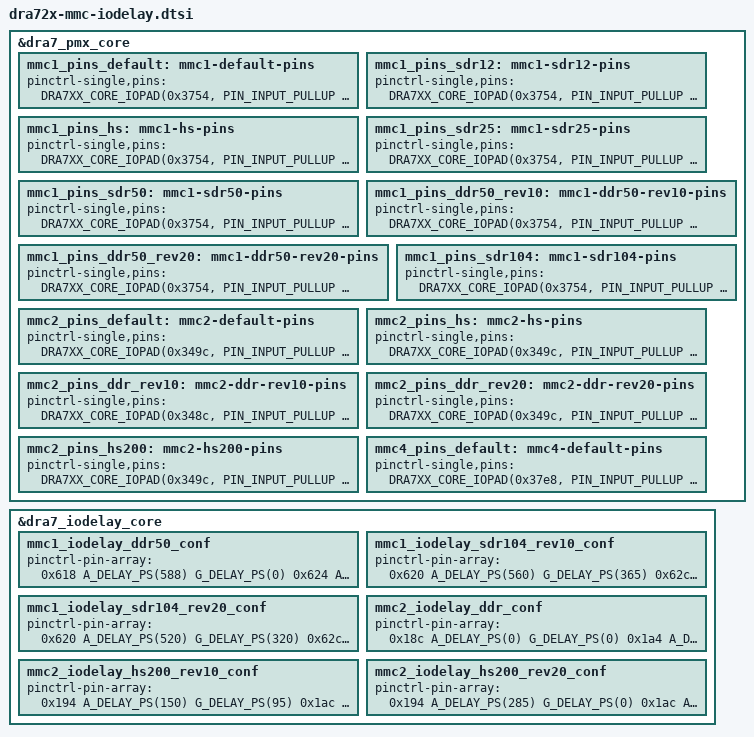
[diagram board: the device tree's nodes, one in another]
&dra7_pmx_core {
	mmc1_pins_default: mmc1-default-pins {
		pinctrl-single,pins = <
			DRA7XX_CORE_IOPAD(0x3754, PIN_INPUT_PULLUP | MUX_MODE0)  
			DRA7XX_CORE_IOPAD(0x3758, PIN_INPUT_PULLUP | MUX_MODE0)  
			DRA7XX_CORE_IOPAD(0x375c, PIN_INPUT_PULLUP | MUX_MODE0)  
			DRA7XX_CORE_IOPAD(0x3760, PIN_INPUT_PULLUP | MUX_MODE0)  
			DRA7XX_CORE_IOPAD(0x3764, PIN_INPUT_PULLUP | MUX_MODE0)  
			DRA7XX_CORE_IOPAD(0x3768, PIN_INPUT_PULLUP | MUX_MODE0)  
		>;
	};
	mmc1_pins_sdr12: mmc1-sdr12-pins {
		pinctrl-single,pins = <
			DRA7XX_CORE_IOPAD(0x3754, PIN_INPUT_PULLUP | MUX_MODE0)	 
			DRA7XX_CORE_IOPAD(0x3758, PIN_INPUT_PULLUP | MUX_MODE0)	 
			DRA7XX_CORE_IOPAD(0x375c, PIN_INPUT_PULLUP | MUX_MODE0)	 
			DRA7XX_CORE_IOPAD(0x3760, PIN_INPUT_PULLUP | MUX_MODE0)	 
			DRA7XX_CORE_IOPAD(0x3764, PIN_INPUT_PULLUP | MUX_MODE0)	 
			DRA7XX_CORE_IOPAD(0x3768, PIN_INPUT_PULLUP | MUX_MODE0)	 
		>;
	};
	mmc1_pins_hs: mmc1-hs-pins {
		pinctrl-single,pins = <
			DRA7XX_CORE_IOPAD(0x3754, PIN_INPUT_PULLUP | MUX_MODE0)  
			DRA7XX_CORE_IOPAD(0x3758, PIN_INPUT_PULLUP | MUX_MODE0)  
			DRA7XX_CORE_IOPAD(0x375c, PIN_INPUT_PULLUP | MUX_MODE0)  
			DRA7XX_CORE_IOPAD(0x3760, PIN_INPUT_PULLUP | MUX_MODE0)  
			DRA7XX_CORE_IOPAD(0x3764, PIN_INPUT_PULLUP | MUX_MODE0)  
			DRA7XX_CORE_IOPAD(0x3768, PIN_INPUT_PULLUP | MUX_MODE0)  
		>;
	};
	mmc1_pins_sdr25: mmc1-sdr25-pins {
		pinctrl-single,pins = <
			DRA7XX_CORE_IOPAD(0x3754, PIN_INPUT_PULLUP | MUX_MODE0)	 
			DRA7XX_CORE_IOPAD(0x3758, PIN_INPUT_PULLUP | MUX_MODE0)	 
			DRA7XX_CORE_IOPAD(0x375c, PIN_INPUT_PULLUP | MUX_MODE0)	 
			DRA7XX_CORE_IOPAD(0x3760, PIN_INPUT_PULLUP | MUX_MODE0)	 
			DRA7XX_CORE_IOPAD(0x3764, PIN_INPUT_PULLUP | MUX_MODE0)	 
			DRA7XX_CORE_IOPAD(0x3768, PIN_INPUT_PULLUP | MUX_MODE0)	 
		>;
	};
	mmc1_pins_sdr50: mmc1-sdr50-pins {
		pinctrl-single,pins = <
			DRA7XX_CORE_IOPAD(0x3754, PIN_INPUT_PULLUP | MUX_VIRTUAL_MODE15 | MUX_MODE0)	 
			DRA7XX_CORE_IOPAD(0x3758, PIN_INPUT_PULLUP | MUX_VIRTUAL_MODE15 | MUX_MODE0)	 
			DRA7XX_CORE_IOPAD(0x375c, PIN_INPUT_PULLUP | MUX_VIRTUAL_MODE15 | MUX_MODE0)	 
			DRA7XX_CORE_IOPAD(0x3760, PIN_INPUT_PULLUP | MUX_VIRTUAL_MODE15 | MUX_MODE0)	 
			DRA7XX_CORE_IOPAD(0x3764, PIN_INPUT_PULLUP | MUX_VIRTUAL_MODE15 | MUX_MODE0)	 
			DRA7XX_CORE_IOPAD(0x3768, PIN_INPUT_PULLUP | MUX_VIRTUAL_MODE15 | MUX_MODE0)	 
		>;
	};
	mmc1_pins_ddr50_rev10: mmc1-ddr50-rev10-pins {
		pinctrl-single,pins = <
			DRA7XX_CORE_IOPAD(0x3754, PIN_INPUT_PULLUP | MUX_VIRTUAL_MODE14 | MUX_MODE0)	 
			DRA7XX_CORE_IOPAD(0x3758, PIN_INPUT_PULLUP | MUX_VIRTUAL_MODE14 | MUX_MODE0)	 
			DRA7XX_CORE_IOPAD(0x375C, PIN_INPUT_PULLUP | MUX_VIRTUAL_MODE14 | MUX_MODE0)	 
			DRA7XX_CORE_IOPAD(0x3760, PIN_INPUT_PULLUP | MUX_VIRTUAL_MODE14 | MUX_MODE0)	 
			DRA7XX_CORE_IOPAD(0x3764, PIN_INPUT_PULLUP | MUX_VIRTUAL_MODE14 | MUX_MODE0)	 
			DRA7XX_CORE_IOPAD(0x3768, PIN_INPUT_PULLUP | MUX_VIRTUAL_MODE14 | MUX_MODE0)	 
		>;
	};
	mmc1_pins_ddr50_rev20: mmc1-ddr50-rev20-pins {
		pinctrl-single,pins = <
			DRA7XX_CORE_IOPAD(0x3754, PIN_INPUT_PULLUP | MODE_SELECT | MUX_MODE0)	 
			DRA7XX_CORE_IOPAD(0x3758, PIN_INPUT_PULLUP | MODE_SELECT | MUX_MODE0)	 
			DRA7XX_CORE_IOPAD(0x375c, PIN_INPUT_PULLUP | MODE_SELECT | MUX_MODE0)	 
			DRA7XX_CORE_IOPAD(0x3760, PIN_INPUT_PULLUP | MODE_SELECT | MUX_MODE0)	 
			DRA7XX_CORE_IOPAD(0x3764, PIN_INPUT_PULLUP | MODE_SELECT | MUX_MODE0)	 
			DRA7XX_CORE_IOPAD(0x3768, PIN_INPUT_PULLUP | MODE_SELECT | MUX_MODE0)	 
		>;
	};
	mmc1_pins_sdr104: mmc1-sdr104-pins {
		pinctrl-single,pins = <
			DRA7XX_CORE_IOPAD(0x3754, PIN_INPUT_PULLUP | MODE_SELECT | MUX_MODE0)	 
			DRA7XX_CORE_IOPAD(0x3758, PIN_INPUT_PULLUP | MODE_SELECT | MUX_MODE0)	 
			DRA7XX_CORE_IOPAD(0x375c, PIN_INPUT_PULLUP | MODE_SELECT | MUX_MODE0)	 
			DRA7XX_CORE_IOPAD(0x3760, PIN_INPUT_PULLUP | MODE_SELECT | MUX_MODE0)	 
			DRA7XX_CORE_IOPAD(0x3764, PIN_INPUT_PULLUP | MODE_SELECT | MUX_MODE0)	 
			DRA7XX_CORE_IOPAD(0x3768, PIN_INPUT_PULLUP | MODE_SELECT | MUX_MODE0)	 
		>;
	};
	mmc2_pins_default: mmc2-default-pins {
		pinctrl-single,pins = <
			DRA7XX_CORE_IOPAD(0x349c, PIN_INPUT_PULLUP | MUX_MODE1)  
			DRA7XX_CORE_IOPAD(0x34b0, PIN_INPUT_PULLUP | MUX_MODE1)  
			DRA7XX_CORE_IOPAD(0x34a0, PIN_INPUT_PULLUP | MUX_MODE1)  
			DRA7XX_CORE_IOPAD(0x34a4, PIN_INPUT_PULLUP | MUX_MODE1)  
			DRA7XX_CORE_IOPAD(0x34a8, PIN_INPUT_PULLUP | MUX_MODE1)  
			DRA7XX_CORE_IOPAD(0x34ac, PIN_INPUT_PULLUP | MUX_MODE1)  
			DRA7XX_CORE_IOPAD(0x348c, PIN_INPUT_PULLUP | MUX_MODE1)  
			DRA7XX_CORE_IOPAD(0x3490, PIN_INPUT_PULLUP | MUX_MODE1)  
			DRA7XX_CORE_IOPAD(0x3494, PIN_INPUT_PULLUP | MUX_MODE1)  
			DRA7XX_CORE_IOPAD(0x3498, PIN_INPUT_PULLUP | MUX_MODE1)  
		>;
	};
	mmc2_pins_hs: mmc2-hs-pins {
		pinctrl-single,pins = <
			DRA7XX_CORE_IOPAD(0x349c, PIN_INPUT_PULLUP | MUX_MODE1)  
			DRA7XX_CORE_IOPAD(0x34b0, PIN_INPUT_PULLUP | MUX_MODE1)  
			DRA7XX_CORE_IOPAD(0x34a0, PIN_INPUT_PULLUP | MUX_MODE1)  
			DRA7XX_CORE_IOPAD(0x34a4, PIN_INPUT_PULLUP | MUX_MODE1)  
			DRA7XX_CORE_IOPAD(0x34a8, PIN_INPUT_PULLUP | MUX_MODE1)  
			DRA7XX_CORE_IOPAD(0x34ac, PIN_INPUT_PULLUP | MUX_MODE1)  
			DRA7XX_CORE_IOPAD(0x348c, PIN_INPUT_PULLUP | MUX_MODE1)  
			DRA7XX_CORE_IOPAD(0x3490, PIN_INPUT_PULLUP | MUX_MODE1)  
			DRA7XX_CORE_IOPAD(0x3494, PIN_INPUT_PULLUP | MUX_MODE1)  
			DRA7XX_CORE_IOPAD(0x3498, PIN_INPUT_PULLUP | MUX_MODE1)  
		>;
	};
	mmc2_pins_ddr_rev10: mmc2-ddr-rev10-pins {
		pinctrl-single,pins = <
			DRA7XX_CORE_IOPAD(0x348c, PIN_INPUT_PULLUP | MUX_MODE1)	 
			DRA7XX_CORE_IOPAD(0x3490, PIN_INPUT_PULLUP | MUX_MODE1)	 
			DRA7XX_CORE_IOPAD(0x3494, PIN_INPUT_PULLUP | MUX_MODE1)	 
			DRA7XX_CORE_IOPAD(0x3498, PIN_INPUT_PULLUP | MUX_MODE1)	 
			DRA7XX_CORE_IOPAD(0x349c, PIN_INPUT_PULLUP | MUX_MODE1)	 
			DRA7XX_CORE_IOPAD(0x34a0, PIN_INPUT_PULLUP | MUX_MODE1)	 
			DRA7XX_CORE_IOPAD(0x34a4, PIN_INPUT_PULLUP | MUX_MODE1)	 
			DRA7XX_CORE_IOPAD(0x34a8, PIN_INPUT_PULLUP | MUX_MODE1)	 
			DRA7XX_CORE_IOPAD(0x34ac, PIN_INPUT_PULLUP | MUX_MODE1)	 
			DRA7XX_CORE_IOPAD(0x34b0, PIN_INPUT_PULLUP | MUX_MODE1)	 
		>;
	};
	mmc2_pins_ddr_rev20: mmc2-ddr-rev20-pins {
		pinctrl-single,pins = <
			DRA7XX_CORE_IOPAD(0x349c, PIN_INPUT_PULLUP | MODE_SELECT | MUX_MODE1)  
			DRA7XX_CORE_IOPAD(0x34b0, PIN_INPUT_PULLUP | MODE_SELECT | MUX_MODE1)  
			DRA7XX_CORE_IOPAD(0x34a0, PIN_INPUT_PULLUP | MODE_SELECT | MUX_MODE1)  
			DRA7XX_CORE_IOPAD(0x34a4, PIN_INPUT_PULLUP | MODE_SELECT | MUX_MODE1)  
			DRA7XX_CORE_IOPAD(0x34a8, PIN_INPUT_PULLUP | MODE_SELECT | MUX_MODE1)  
			DRA7XX_CORE_IOPAD(0x34ac, PIN_INPUT_PULLUP | MODE_SELECT | MUX_MODE1)  
			DRA7XX_CORE_IOPAD(0x348c, PIN_INPUT_PULLUP | MODE_SELECT | MUX_MODE1)  
			DRA7XX_CORE_IOPAD(0x3490, PIN_INPUT_PULLUP | MODE_SELECT | MUX_MODE1)  
			DRA7XX_CORE_IOPAD(0x3494, PIN_INPUT_PULLUP | MODE_SELECT | MUX_MODE1)  
			DRA7XX_CORE_IOPAD(0x3498, PIN_INPUT_PULLUP | MODE_SELECT | MUX_MODE1)  
		>;
	};
	mmc2_pins_hs200: mmc2-hs200-pins {
		pinctrl-single,pins = <
			DRA7XX_CORE_IOPAD(0x349c, PIN_INPUT_PULLUP | MODE_SELECT | MUX_MODE1)  
			DRA7XX_CORE_IOPAD(0x34b0, PIN_INPUT_PULLUP | MODE_SELECT | MUX_MODE1)  
			DRA7XX_CORE_IOPAD(0x34a0, PIN_INPUT_PULLUP | MODE_SELECT | MUX_MODE1)  
			DRA7XX_CORE_IOPAD(0x34a4, PIN_INPUT_PULLUP | MODE_SELECT | MUX_MODE1)  
			DRA7XX_CORE_IOPAD(0x34a8, PIN_INPUT_PULLUP | MODE_SELECT | MUX_MODE1)  
			DRA7XX_CORE_IOPAD(0x34ac, PIN_INPUT_PULLUP | MODE_SELECT | MUX_MODE1)  
			DRA7XX_CORE_IOPAD(0x348c, PIN_INPUT_PULLUP | MODE_SELECT | MUX_MODE1)  
			DRA7XX_CORE_IOPAD(0x3490, PIN_INPUT_PULLUP | MODE_SELECT | MUX_MODE1)  
			DRA7XX_CORE_IOPAD(0x3494, PIN_INPUT_PULLUP | MODE_SELECT | MUX_MODE1)  
			DRA7XX_CORE_IOPAD(0x3498, PIN_INPUT_PULLUP | MODE_SELECT | MUX_MODE1)  
		>;
	};
	mmc4_pins_default: mmc4-default-pins {
		pinctrl-single,pins = <
			DRA7XX_CORE_IOPAD(0x37e8, PIN_INPUT_PULLUP | MUX_MODE3)  
			DRA7XX_CORE_IOPAD(0x37ec, PIN_INPUT_PULLUP | MUX_MODE3)  
			DRA7XX_CORE_IOPAD(0x37f0, PIN_INPUT_PULLUP | MUX_MODE3)  
			DRA7XX_CORE_IOPAD(0x37f4, PIN_INPUT_PULLUP | MUX_MODE3)  
			DRA7XX_CORE_IOPAD(0x37f8, PIN_INPUT_PULLUP | MUX_MODE3)  
			DRA7XX_CORE_IOPAD(0x37fc, PIN_INPUT_PULLUP | MUX_MODE3)  
		>;
	};
};
&dra7_iodelay_core {
	mmc1_iodelay_ddr50_conf: mmc1_iodelay_ddr50_conf {
		pinctrl-pin-array = <
			0x618 A_DELAY_PS(588) G_DELAY_PS(0)	 
			0x624 A_DELAY_PS(1000) G_DELAY_PS(0)	 
			0x630 A_DELAY_PS(1375) G_DELAY_PS(0)	 
			0x63C A_DELAY_PS(1000) G_DELAY_PS(0)	 
			0x648 A_DELAY_PS(1000) G_DELAY_PS(0)	 
			0x654 A_DELAY_PS(1000) G_DELAY_PS(0)	 
			0x620 A_DELAY_PS(1230) G_DELAY_PS(0)	 
			0x62C A_DELAY_PS(0) G_DELAY_PS(0)	 
			0x638 A_DELAY_PS(56) G_DELAY_PS(0)	 
			0x644 A_DELAY_PS(76) G_DELAY_PS(0)	 
			0x650 A_DELAY_PS(91) G_DELAY_PS(0)	 
			0x65C A_DELAY_PS(99) G_DELAY_PS(0)	 
			0x628 A_DELAY_PS(0) G_DELAY_PS(0)	 
			0x634 A_DELAY_PS(0) G_DELAY_PS(0)	 
			0x640 A_DELAY_PS(0) G_DELAY_PS(0)	 
			0x64C A_DELAY_PS(0) G_DELAY_PS(0)	 
			0x658 A_DELAY_PS(0) G_DELAY_PS(0)	 
		>;
	};
	mmc1_iodelay_sdr104_rev10_conf: mmc1_iodelay_sdr104_rev10_conf {
		pinctrl-pin-array = <
			0x620 A_DELAY_PS(560) G_DELAY_PS(365)	 
			0x62c A_DELAY_PS(0) G_DELAY_PS(0)	 
			0x638 A_DELAY_PS(29) G_DELAY_PS(0)	 
			0x644 A_DELAY_PS(0) G_DELAY_PS(0)	 
			0x650 A_DELAY_PS(47) G_DELAY_PS(0)	 
			0x65c A_DELAY_PS(30) G_DELAY_PS(0)	 
			0x628 A_DELAY_PS(125) G_DELAY_PS(0)	 
			0x634 A_DELAY_PS(43) G_DELAY_PS(0)	 
			0x640 A_DELAY_PS(433) G_DELAY_PS(0)	 
			0x64c A_DELAY_PS(287) G_DELAY_PS(0)	 
			0x658 A_DELAY_PS(351) G_DELAY_PS(0)	 
		>;
	};
	mmc1_iodelay_sdr104_rev20_conf: mmc1_iodelay_sdr104_rev20_conf {
		pinctrl-pin-array = <
			0x620 A_DELAY_PS(520) G_DELAY_PS(320)	 
			0x62c A_DELAY_PS(0) G_DELAY_PS(0)	 
			0x638 A_DELAY_PS(40) G_DELAY_PS(0)	 
			0x644 A_DELAY_PS(83) G_DELAY_PS(0)	 
			0x650 A_DELAY_PS(98) G_DELAY_PS(0)	 
			0x65c A_DELAY_PS(106) G_DELAY_PS(0)	 
			0x628 A_DELAY_PS(51) G_DELAY_PS(0)	 
			0x634 A_DELAY_PS(0) G_DELAY_PS(0)	 
			0x640 A_DELAY_PS(363) G_DELAY_PS(0)	 
			0x64c A_DELAY_PS(199) G_DELAY_PS(0)	 
			0x658 A_DELAY_PS(273) G_DELAY_PS(0)	 
		>;
	};
	mmc2_iodelay_ddr_conf: mmc2_iodelay_ddr_conf {
		pinctrl-pin-array = <
			0x18c A_DELAY_PS(0) G_DELAY_PS(0)	 
			0x1a4 A_DELAY_PS(119) G_DELAY_PS(0)	 
			0x1b0 A_DELAY_PS(0) G_DELAY_PS(0)	 
			0x1bc A_DELAY_PS(18) G_DELAY_PS(0)	 
			0x1c8 A_DELAY_PS(894) G_DELAY_PS(0)	 
			0x1d4 A_DELAY_PS(30) G_DELAY_PS(0)	 
			0x1e0 A_DELAY_PS(0) G_DELAY_PS(0)	 
			0x1ec A_DELAY_PS(23) G_DELAY_PS(0)	 
			0x1f8 A_DELAY_PS(0) G_DELAY_PS(0)	 
			0x360 A_DELAY_PS(0) G_DELAY_PS(0)	 
			0x194 A_DELAY_PS(152) G_DELAY_PS(0)	 
			0x1ac A_DELAY_PS(206) G_DELAY_PS(0)	 
			0x1b8 A_DELAY_PS(78) G_DELAY_PS(0)	 
			0x1c4 A_DELAY_PS(2) G_DELAY_PS(0)	 
			0x1d0 A_DELAY_PS(266) G_DELAY_PS(0)	 
			0x1dc A_DELAY_PS(0) G_DELAY_PS(0)	 
			0x1e8 A_DELAY_PS(0) G_DELAY_PS(0)	 
			0x1f4 A_DELAY_PS(43) G_DELAY_PS(0)	 
			0x200 A_DELAY_PS(0) G_DELAY_PS(0)	 
			0x368 A_DELAY_PS(0) G_DELAY_PS(0)	 
			0x190 A_DELAY_PS(0) G_DELAY_PS(0)	 
			0x1a8 A_DELAY_PS(0) G_DELAY_PS(0)	 
			0x1b4 A_DELAY_PS(0) G_DELAY_PS(0)	 
			0x1c0 A_DELAY_PS(0) G_DELAY_PS(0)	 
			0x1d8 A_DELAY_PS(0) G_DELAY_PS(0)	 
			0x1e4 A_DELAY_PS(0) G_DELAY_PS(0)	 
			0x1f0 A_DELAY_PS(0) G_DELAY_PS(0)	 
			0x1fc A_DELAY_PS(0) G_DELAY_PS(0)	 
			0x364 A_DELAY_PS(0) G_DELAY_PS(0)	 
		>;
	};
	mmc2_iodelay_hs200_rev10_conf: mmc2_iodelay_hs200_rev10_conf {
		pinctrl-pin-array = <
			0x194 A_DELAY_PS(150) G_DELAY_PS(95)	 
			0x1ac A_DELAY_PS(250) G_DELAY_PS(0)	 
			0x1b8 A_DELAY_PS(125) G_DELAY_PS(0)	 
			0x1c4 A_DELAY_PS(100) G_DELAY_PS(0)	 
			0x1d0 A_DELAY_PS(870) G_DELAY_PS(415)	 
			0x1dc A_DELAY_PS(30) G_DELAY_PS(0)	 
			0x1e8 A_DELAY_PS(200) G_DELAY_PS(0)	 
			0x1f4 A_DELAY_PS(200) G_DELAY_PS(0)	 
			0x200 A_DELAY_PS(0) G_DELAY_PS(0)	 
			0x368 A_DELAY_PS(240) G_DELAY_PS(0)	 
			0x190 A_DELAY_PS(695) G_DELAY_PS(0)	 
			0x1a8 A_DELAY_PS(924) G_DELAY_PS(0)	 
			0x1b4 A_DELAY_PS(719) G_DELAY_PS(0)	 
			0x1c0 A_DELAY_PS(824) G_DELAY_PS(0)	 
			0x1d8 A_DELAY_PS(877) G_DELAY_PS(0)	 
			0x1e4 A_DELAY_PS(446) G_DELAY_PS(0)	 
			0x1f0 A_DELAY_PS(847) G_DELAY_PS(0)	 
			0x1fc A_DELAY_PS(586) G_DELAY_PS(0)	 
			0x364 A_DELAY_PS(1039) G_DELAY_PS(0)	 
		>;
	};
	mmc2_iodelay_hs200_rev20_conf: mmc2_iodelay_hs200_rev20_conf {
		pinctrl-pin-array = <
			0x194 A_DELAY_PS(285) G_DELAY_PS(0)	 
			0x1ac A_DELAY_PS(189) G_DELAY_PS(0)	 
			0x1b8 A_DELAY_PS(0) G_DELAY_PS(120)	 
			0x1c4 A_DELAY_PS(0) G_DELAY_PS(70)	 
			0x1d0 A_DELAY_PS(730) G_DELAY_PS(360)	 
			0x1dc A_DELAY_PS(0) G_DELAY_PS(0)	 
			0x1e8 A_DELAY_PS(0) G_DELAY_PS(0)	 
			0x1f4 A_DELAY_PS(70) G_DELAY_PS(0)	 
			0x200 A_DELAY_PS(0) G_DELAY_PS(0)	 
			0x368 A_DELAY_PS(0) G_DELAY_PS(120)	 
			0x190 A_DELAY_PS(0) G_DELAY_PS(0)	 
			0x1a8 A_DELAY_PS(231) G_DELAY_PS(0)	 
			0x1b4 A_DELAY_PS(39) G_DELAY_PS(0)	 
			0x1c0 A_DELAY_PS(91) G_DELAY_PS(0)	 
			0x1d8 A_DELAY_PS(176) G_DELAY_PS(0)	 
			0x1e4 A_DELAY_PS(0) G_DELAY_PS(0)	 
			0x1f0 A_DELAY_PS(101) G_DELAY_PS(0)	 
			0x1fc A_DELAY_PS(0) G_DELAY_PS(0)	 
			0x364 A_DELAY_PS(360) G_DELAY_PS(0)	 
		>;
	};
};
